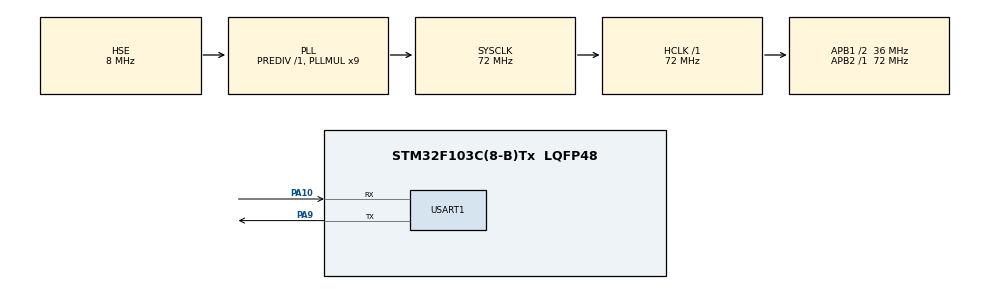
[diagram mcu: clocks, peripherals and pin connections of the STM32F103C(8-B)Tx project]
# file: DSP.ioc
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Mcu.Family=STM32F1
Mcu.Name=STM32F103C(8-B)Tx
Mcu.Package=LQFP48
NVIC.PriorityGroup=NVIC_PRIORITYGROUP_4
PA10.Mode=Asynchronous
PA10.Signal=USART1_RX
PA13.Mode=Serial_Wire
PA13.Signal=SYS_JTMS-SWDIO
PA14.Mode=Serial_Wire
PA14.Signal=SYS_JTCK-SWCLK
PA9.Mode=Asynchronous
PA9.Signal=USART1_TX
PC14-OSC32_IN.Mode=LSE-External-Oscillator
PC14-OSC32_IN.Signal=RCC_OSC32_IN
PC15-OSC32_OUT.Mode=LSE-External-Oscillator
PC15-OSC32_OUT.Signal=RCC_OSC32_OUT
PD0-OSC_IN.Mode=HSE-External-Oscillator
PD0-OSC_IN.Signal=RCC_OSC_IN
PD1-OSC_OUT.Mode=HSE-External-Oscillator
PD1-OSC_OUT.Signal=RCC_OSC_OUT
ProjectManager.HeapSize=0x800
ProjectManager.StackSize=0x1000
ProjectManager.TargetToolchain=MDK-ARM V5
RCC.AHBFreq_Value=72000000
RCC.APB1CLKDivider=RCC_HCLK_DIV2
RCC.APB1Freq_Value=36000000
RCC.APB1TimFreq_Value=72000000
RCC.APB2Freq_Value=72000000
RCC.APB2TimFreq_Value=72000000
RCC.HCLKFreq_Value=72000000
RCC.PLLMUL=RCC_PLL_MUL9
RCC.PLLSourceVirtual=RCC_PLLSOURCE_HSE
RCC.SYSCLKFreq_VALUE=72000000
RCC.SYSCLKSource=RCC_SYSCLKSOURCE_PLLCLK
RCC.USBFreq_Value=72000000
USART1.VirtualMode=VM_ASYNC
board=DSP

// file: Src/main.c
/* USER CODE BEGIN Header */
/**
  ******************************************************************************
  * @file           : main.c
  * @brief          : Main program body
  ******************************************************************************
  ** This notice applies to any and all portions of this file
  * that are not between comment pairs USER CODE BEGIN and
  * USER CODE END. Other portions of this file, whether
  * inserted by the user or by software development tools
  * are owned by their respective copyright owners.
  *
  * COPYRIGHT(c) 2018 STMicroelectronics
  *
  * Redistribution and use in source and binary forms, with or without modification,
  * are permitted provided that the following conditions are met:
  *   1. Redistributions of source code must retain the above copyright notice,
  *      this list of conditions and the following disclaimer.
  *   2. Redistributions in binary form must reproduce the above copyright notice,
  *      this list of conditions and the following disclaimer in the documentation
  *      and/or other materials provided with the distribution.
  *   3. Neither the name of STMicroelectronics nor the names of its contributors
  *      may be used to endorse or promote products derived from this software
  *      without specific prior written permission.
  *
  * THIS SOFTWARE IS PROVIDED BY THE COPYRIGHT HOLDERS AND CONTRIBUTORS "AS IS"
  * AND ANY EXPRESS OR IMPLIED WARRANTIES, INCLUDING, BUT NOT LIMITED TO, THE
  * IMPLIED WARRANTIES OF MERCHANTABILITY AND FITNESS FOR A PARTICULAR PURPOSE ARE
  * DISCLAIMED. IN NO EVENT SHALL THE COPYRIGHT HOLDER OR CONTRIBUTORS BE LIABLE
  * FOR ANY DIRECT, INDIRECT, INCIDENTAL, SPECIAL, EXEMPLARY, OR CONSEQUENTIAL
  * DAMAGES (INCLUDING, BUT NOT LIMITED TO, PROCUREMENT OF SUBSTITUTE GOODS OR
  * SERVICES; LOSS OF USE, DATA, OR PROFITS; OR BUSINESS INTERRUPTION) HOWEVER
  * CAUSED AND ON ANY THEORY OF LIABILITY, WHETHER IN CONTRACT, STRICT LIABILITY,
  * OR TORT (INCLUDING NEGLIGENCE OR OTHERWISE) ARISING IN ANY WAY OUT OF THE USE
  * OF THIS SOFTWARE, EVEN IF ADVISED OF THE POSSIBILITY OF SUCH DAMAGE.
  *
  ******************************************************************************
  */
/* USER CODE END Header */

#include "main.h"
#include "usart.h"
#include "gpio.h"

/* USER CODE BEGIN Includes */
#include "arm_math.h"
#include "printf_scanf.h"
/* USER CODE END Includes */

/* USER CODE BEGIN PV */
/* Private variables ---------------------------------------------------------*/

float32_t  neg=-1;
float32_t  A=50.5684,B=100.0f,ZERO=0;
float32_t  input[10]={1.0f,2.0f,3.0f,4.0f,5.0f,6.0f,7.0f,8.0f,9.0f,10.0f};
float32_t  out,out_1;
uint32_t   Max_index,Min_index;

float32_t max,min,m_number[2],voltage[10],temp,voltage_sum;  uint32_t  max_loc,min_loc;
uint32_t ADC_Converted_array[]={4000,4000,4000,6000,4000,4000,4000,4000,4000,1000};

#define Buffer_Length  1024
#define TEST_LENGTH_SAMPLES 2048

__IO uint16_t ADC_Convert_Data[Buffer_Length];
float32_t testInput_f32_10khz[TEST_LENGTH_SAMPLES];
float32_t testOutput[TEST_LENGTH_SAMPLES/2];

arm_cfft_instance_f32 arm_cfft_sR_f32_len1024;
uint32_t fftSize = 1024;
uint32_t ifftFlag = 0;
uint32_t doBitReverse = 1;

/* USER CODE END PV */

void SystemClock_Config(void);
/* USER CODE BEGIN PFP */
/* Private function prototypes -----------------------------------------------*/

/* USER CODE END PFP */

int main(void)
{
  /* USER CODE BEGIN 1 */
  uint32_t i,j;

  /* USER CODE END 1 */

  /* MCU Configuration--------------------------------------------------------*/

  /* Reset of all peripherals, Initializes the Flash interface and the Systick. */
  HAL_Init();

  /* Configure the system clock */
  SystemClock_Config();

  /* Initialize all configured peripherals */
  MX_GPIO_Init();
  MX_USART1_UART_Init();
  /* USER CODE BEGIN 2 */

    arm_abs_f32(&neg,&out,1);
    arm_negate_f32(&neg,&out,1);
    arm_add_f32(&A,&B,&out,1);

     out_1=arm_cos_f32( 0.5*3.1415);
     arm_sin_cos_f32(60, &out, &out_1);// degree  sin   cos

     arm_max_f32(input, 10, &out_1, &Max_index);//输入数组，大小，输出最大数，最大数位置。
     arm_min_f32(input, 10, &out_1, &Min_index);//输入数组，大小，输出最小数，最小数位置。

     arm_mean_f32(input, 10, &out_1);//平均值
     arm_std_f32(input, 10, &out_1);//标准偏差
     arm_rms_f32(input, 10, &out_1);//均方根
     arm_var_f32(input, 10, &out_1);//方差

                    for(i=0;i<10;i++)                      //输出去大，小的采样值
           {
             voltage[i]=ADC_Converted_array[i]*3.3/65535;
           }

     arm_max_f32(voltage, 10, &max, &max_loc);//输入数组，大小，输出最大数，最大数位置。
     arm_min_f32(voltage, 10, &min, &min_loc);//输入数组，大小，输出最小数，最小数位置。
     m_number[0]=max;
     m_number[1]=min;

          for(j=0;j<10;j++)                      //输出去大，小的采样值
           {
           //arm_add_f32(&voltage[j],&voltage_sum,&voltage_sum,10);
            voltage_sum += voltage[j];
           }
     arm_sub_f32(&voltage_sum,m_number,&voltage_sum,2);//A-B[].
     //voltage_sum= voltage_sum-max-min;
     arm_mean_f32(&voltage_sum, 8, &temp);//平均值

   	for(i=0; i<1024; i++)
	{
		testInput_f32_10khz[i*2+1] = 0;
		testInput_f32_10khz[i*2] = ADC_Convert_Data[i];
	}

	 /* Process the data through the CFFT/CIFFT module */
  arm_cfft_f32(&arm_cfft_sR_f32_len1024, testInput_f32_10khz, ifftFlag, doBitReverse);

  /* Process the data through the Complex Magnitude Module for
  calculating the magnitude at each bin */
  arm_cmplx_mag_f32(testInput_f32_10khz, testOutput, fftSize);

	/* Print fft result data*/
	printf("ADC_FFT Value\r\n");

	for(i=0; i<fftSize; i++)
	{

		printf("\r\n");
		printf("%d\r\t", (uint32_t)testOutput[i]);
	}

  /* USER CODE END 2 */

  /* Infinite loop */
  while (1)
  {

  }
}

void SystemClock_Config(void)
{
  RCC_OscInitTypeDef RCC_OscInitStruct = {0};
  RCC_ClkInitTypeDef RCC_ClkInitStruct = {0};

  /**Initializes the CPU, AHB and APB busses clocks
  */
  RCC_OscInitStruct.OscillatorType = RCC_OSCILLATORTYPE_HSE;
  RCC_OscInitStruct.HSEState = RCC_HSE_ON;
  RCC_OscInitStruct.HSEPredivValue = RCC_HSE_PREDIV_DIV1;
  RCC_OscInitStruct.HSIState = RCC_HSI_ON;
  RCC_OscInitStruct.PLL.PLLState = RCC_PLL_ON;
  RCC_OscInitStruct.PLL.PLLSource = RCC_PLLSOURCE_HSE;
  RCC_OscInitStruct.PLL.PLLMUL = RCC_PLL_MUL9;
  if (HAL_RCC_OscConfig(&RCC_OscInitStruct) != HAL_OK)
  {
    Error_Handler();
  }
  /**Initializes the CPU, AHB and APB busses clocks
  */
  RCC_ClkInitStruct.ClockType = RCC_CLOCKTYPE_HCLK|RCC_CLOCKTYPE_SYSCLK
                              |RCC_CLOCKTYPE_PCLK1|RCC_CLOCKTYPE_PCLK2;
  RCC_ClkInitStruct.SYSCLKSource = RCC_SYSCLKSOURCE_PLLCLK;
  RCC_ClkInitStruct.AHBCLKDivider = RCC_SYSCLK_DIV1;
  RCC_ClkInitStruct.APB1CLKDivider = RCC_HCLK_DIV2;
  RCC_ClkInitStruct.APB2CLKDivider = RCC_HCLK_DIV1;

  if (HAL_RCC_ClockConfig(&RCC_ClkInitStruct, FLASH_LATENCY_2) != HAL_OK)
  {
    Error_Handler();
  }
}

void Error_Handler(void)
{
  while(1)
  {
  }
}

/************************ (C) COPYRIGHT STMicroelectronics *****END OF FILE****/
